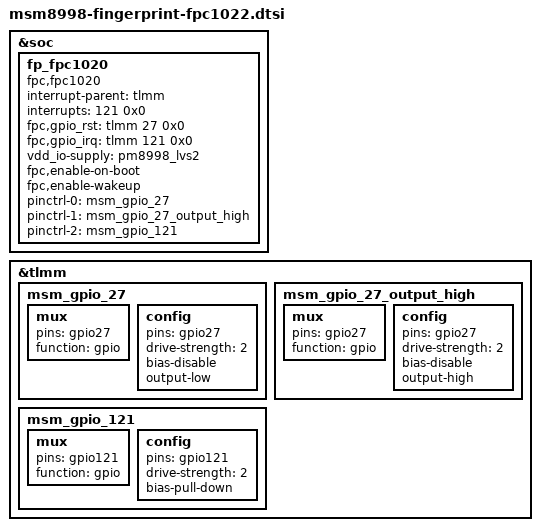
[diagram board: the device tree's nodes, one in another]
/* Copyright (c) 2017, The Linux Foundation. All rights reserved.
 *
 * This program is free software; you can redistribute it and/or modify
 * it under the terms of the GNU General Public License version 2 and
 * only version 2 as published by the Free Software Foundation.
 *
 * This program is distributed in the hope that it will be useful,
 * but WITHOUT ANY WARRANTY; without even the implied warranty of
 * MERCHANTABILITY or FITNESS FOR A PARTICULAR PURPOSE.  See the
 * GNU General Public License for more details.
 */

&soc {
	fp_fpc1020 {
		status = "ok";
		compatible = "fpc,fpc1020";
		interrupt-parent = <&tlmm>;
		interrupts = <121 0x0>;
		fpc,gpio_rst    = <&tlmm 27 0x0>;
		fpc,gpio_irq    = <&tlmm 121 0x0>;
		/* vcc_spi-supply  = <&pm8994_s4>; */
		vdd_io-supply   = <&pm8998_lvs2>;
		/* vdd_ana-supply  = <&pm8996_l18>; */
		fpc,enable-on-boot;
		fpc,enable-wakeup;

		pinctrl-names = "fpc1020_reset_reset",
			"fpc1020_reset_active",
			"fpc1020_irq_active";

		pinctrl-0 = <&msm_gpio_27>;
		pinctrl-1 = <&msm_gpio_27_output_high>;
		pinctrl-2 = <&msm_gpio_121>;
	};
};

&tlmm {
	/* GPIO_27 : FP_RESET_N */
	msm_gpio_27: msm_gpio_27 {
		mux {
			 pins = "gpio27";
			 function = "gpio";
		};

		config {
			pins = "gpio27";
			drive-strength = <2>;
			bias-disable;
			output-low;
		};
	};

	/* GPIO_27 : FP_RESET_N, state device active*/
	msm_gpio_27_output_high: msm_gpio_27_output_high {
		mux {
			pins = "gpio27";
			function = "gpio";
		};

		config {
			pins = "gpio27";
			drive-strength = <2>;
			bias-disable;
			output-high;
		};
	};

	/* GPIO_86 : FP_INT_N */
	msm_gpio_121: msm_gpio_121 {
		mux {
			pins = "gpio121";
			function = "gpio";
		};

		config {
			pins = "gpio121";
			drive-strength = <2>;
			bias-pull-down;
		};
	};
};
